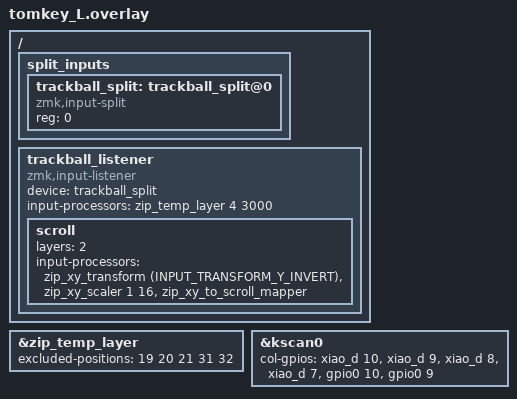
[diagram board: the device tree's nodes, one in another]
#include "tomkey.dtsi"
#include <dt-bindings/zmk/input_transform.h>
#include <input/processors.dtsi>
#include <zephyr/dt-bindings/input/input-event-codes.h>

/ {
    split_inputs {
        #address-cells = <1>;
        #size-cells = <0>;

        trackball_split: trackball_split@0 {
            compatible = "zmk,input-split";
            reg = <0>;
        };
    };

    trackball_listener: trackball_listener {
        compatible = "zmk,input-listener";
        status = "disabled";
        device = <&trackball_split>;
    };
};

&zip_temp_layer {
    excluded-positions = <
        // T（右クリック）,N（左クリック）,S（スクロール）のキー
        19
        20
        21
        // D（戻る）,M（進む）
        31
        32
    >;
};

&trackball_listener {
    status = "okay";
    // 以下はトラックボールに触れられた時にレイヤー4を3000ms有効にするというコード
    input-processors = <&zip_temp_layer 4 3000>;

    scroll {
        layers = <2>;
        input-processors = <&zip_xy_transform (INPUT_TRANSFORM_Y_INVERT)>, <&zip_xy_scaler 1 16>, <&zip_xy_to_scroll_mapper>;
    };
};


&kscan0 {
        col-gpios
            = <&xiao_d 10 GPIO_ACTIVE_HIGH>
            , <&xiao_d 9 GPIO_ACTIVE_HIGH>
            , <&xiao_d 8 GPIO_ACTIVE_HIGH>
            , <&xiao_d 7 GPIO_ACTIVE_HIGH>
            , <&gpio0 10 GPIO_ACTIVE_HIGH>
            , <&gpio0 9 GPIO_ACTIVE_HIGH>
            ;
};
